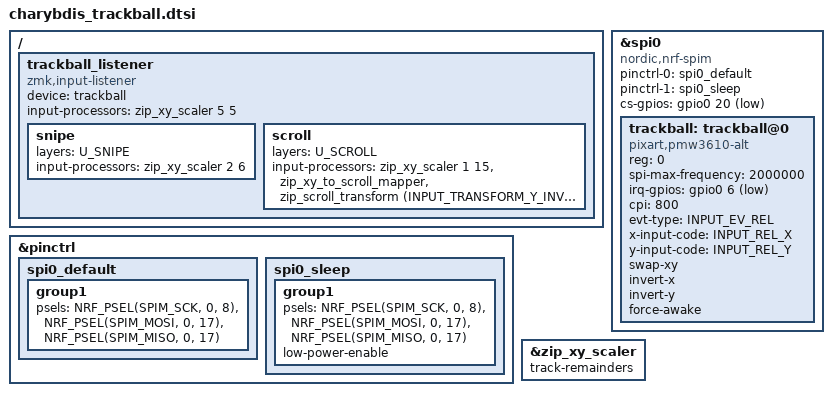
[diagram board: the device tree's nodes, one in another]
#include <zephyr/dt-bindings/input/input-event-codes.h>
#include <input/processors.dtsi>
#include <dt-bindings/zmk/input_transform.h>
#include "charybdis_layers.h"

&pinctrl {
    spi0_default: spi0_default {
        group1 {
            psels = <NRF_PSEL(SPIM_SCK, 0, 8)>,
                <NRF_PSEL(SPIM_MOSI, 0, 17)>,
                <NRF_PSEL(SPIM_MISO, 0, 17)>;
        };
    };

    spi0_sleep: spi0_sleep {
        group1 {
            psels = <NRF_PSEL(SPIM_SCK, 0, 8)>,
                <NRF_PSEL(SPIM_MOSI, 0, 17)>,
                <NRF_PSEL(SPIM_MISO, 0, 17)>;
            low-power-enable;
        };
    };
};

&spi0 {
    status = "okay";
    compatible = "nordic,nrf-spim";
    pinctrl-0 = <&spi0_default>;
    pinctrl-1 = <&spi0_sleep>;
    pinctrl-names = "default", "sleep";
    cs-gpios = <&gpio0 20 GPIO_ACTIVE_LOW>;

    trackball: trackball@0 {
        status = "okay";
        compatible = "pixart,pmw3610-alt";
        reg = <0>;
        spi-max-frequency = <2000000>;
        irq-gpios = <&gpio0 6 (GPIO_ACTIVE_LOW | GPIO_PULL_UP)>;
        cpi = <800>;
        evt-type = <INPUT_EV_REL>;
        x-input-code = <INPUT_REL_X>;
        y-input-code = <INPUT_REL_Y>;

        swap-xy;
        invert-x;
        invert-y;

        force-awake;
    };
};

&zip_xy_scaler { track-remainders; };

/ {
    trackball_listener: trackball_listener {
        compatible = "zmk,input-listener";
        status = "okay";
        device = <&trackball>;
        input-processors = <&zip_xy_scaler 5 5>;

        snipe {
            layers = <U_SNIPE>;
            input-processors = <&zip_xy_scaler 2 6>;
        };

        scroll {
            layers = <U_SCROLL>;
            input-processors = <
                &zip_xy_scaler 1 15
                &zip_xy_to_scroll_mapper
                &zip_scroll_transform (INPUT_TRANSFORM_Y_INVERT)
            >;
        };
    };
};
